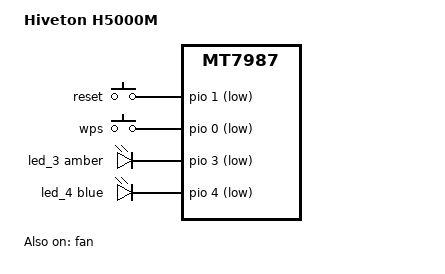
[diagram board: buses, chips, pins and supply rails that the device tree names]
// SPDX-License-Identifier: (GPL-2.0 OR MIT)
/*
 * Copyright (C) 2025 MediaTek Inc.
 * Author: Sam.Shih <sam.shih@mediatek.com>
 */

/dts-v1/;
#include "mt7987a.dtsi"
#include <dt-bindings/input/input.h>
#include "mt7987-emmc.dtsi"

/* MT7987A RFB DTS for DT overlay-based device tree */
/ {
	model = "Hiveton H5000M";
	compatible = "hiveton,h5000m", "mediatek,mt7987";

	chosen {
		bootargs = "console=ttyS0,115200n1 \
			    earlycon=uart8250,mmio32,0x11000000 \
			    root=PARTLABEL=rootfs rootwait";
	};

	gpio-keys {
		compatible = "gpio-keys";

		reset {
			label = "reset";
			linux,code = <KEY_RESTART>;
			gpios = <&pio 1 GPIO_ACTIVE_LOW>;
			debounce-interval = <10>;
		};

		wps {
			label = "wps";
			linux,code = <KEY_WPS_BUTTON>;
			gpios = <&pio 0 GPIO_ACTIVE_LOW>;
			debounce-interval = <10>;
		};
	};
	
	leds {
		compatible = "gpio-leds";

		led_3: led-3 {
			function = LED_FUNCTION_WLAN_2GHZ;
			color = <LED_COLOR_ID_AMBER>;
			gpios = <&pio 3 GPIO_ACTIVE_LOW>;
		};

		led_4: led-4 {
			function = LED_FUNCTION_WLAN_5GHZ;
			color = <LED_COLOR_ID_BLUE>;
			gpios = <&pio 4 GPIO_ACTIVE_LOW>;
		};
	};
};

&fan {
	pinctrl-names = "default";
        pinctrl-0 = <&pwm_fan_pins>;
	compatible = "pwm-fan";
	#cooling-cells = <2>;
	cooling-levels = <0 10 20 30 40 50 60 70 80 90 100 110 120 130 140 150 160 170 180 190 200 210 220 240 255>;
	pwms = <&pwm 1 50000 0>;
	status = "okay";
};
